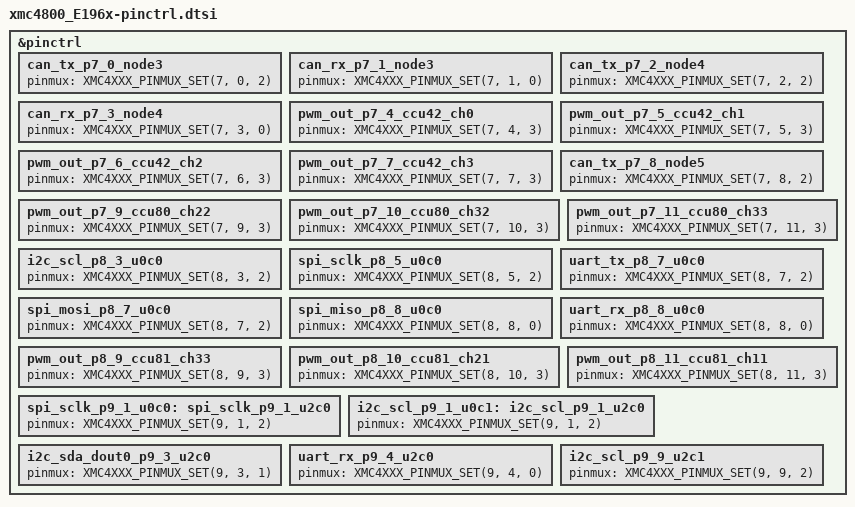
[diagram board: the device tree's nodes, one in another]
/*
 * SPDX-FileCopyrightText: Karl Palsson 2026 <karl.palsson@marel.com>
 * SPDX-License-Identifier: Apache-2.0
 */

#include <infineon/cat3/xmc/xmc4xxx.dtsi>
#include <zephyr/dt-bindings/pinctrl/xmc4xxx-pinctrl.h>
#include <infineon/cat3/xmc/xmc4700_F144x2048-pinctrl.dtsi>

&pinctrl {
	/omit-if-no-ref/ can_tx_p7_0_node3: can_tx_p7_0_node3 {
		pinmux = <XMC4XXX_PINMUX_SET(7, 0, 2)>;
	};

	/omit-if-no-ref/ can_rx_p7_1_node3: can_rx_p7_1_node3 {
		pinmux = <XMC4XXX_PINMUX_SET(7, 1, 0)>; /* CAN input src = RXDC */
	};

	/omit-if-no-ref/ can_tx_p7_2_node4: can_tx_p7_2_node4 {
		pinmux = <XMC4XXX_PINMUX_SET(7, 2, 2)>;
	};

	/omit-if-no-ref/ can_rx_p7_3_node4: can_rx_p7_3_node4 {
		pinmux = <XMC4XXX_PINMUX_SET(7, 3, 0)>; /* CAN input src = RXDC */
	};

	/omit-if-no-ref/ pwm_out_p7_4_ccu42_ch0: pwm_out_p7_4_ccu42_ch0 {
		pinmux = <XMC4XXX_PINMUX_SET(7, 4, 3)>;
	};

	/omit-if-no-ref/ pwm_out_p7_5_ccu42_ch1: pwm_out_p7_5_ccu42_ch1 {
		pinmux = <XMC4XXX_PINMUX_SET(7, 5, 3)>;
	};

	/omit-if-no-ref/ pwm_out_p7_6_ccu42_ch2: pwm_out_p7_6_ccu42_ch2 {
		pinmux = <XMC4XXX_PINMUX_SET(7, 6, 3)>;
	};

	/omit-if-no-ref/ pwm_out_p7_7_ccu42_ch3: pwm_out_p7_7_ccu42_ch3 {
		pinmux = <XMC4XXX_PINMUX_SET(7, 7, 3)>;
	};

	/omit-if-no-ref/ can_tx_p7_8_node5: can_tx_p7_8_node5 {
		pinmux = <XMC4XXX_PINMUX_SET(7, 8, 2)>;
	};

	/omit-if-no-ref/ pwm_out_p7_9_ccu80_ch22: pwm_out_p7_9_ccu80_ch22 {
		pinmux = <XMC4XXX_PINMUX_SET(7, 9, 3)>;
	};

	/omit-if-no-ref/ pwm_out_p7_10_ccu80_ch32: pwm_out_p7_10_ccu80_ch32 {
		pinmux = <XMC4XXX_PINMUX_SET(7, 10, 3)>;
	};

	/omit-if-no-ref/ pwm_out_p7_11_ccu80_ch33: pwm_out_p7_11_ccu80_ch33 {
		pinmux = <XMC4XXX_PINMUX_SET(7, 11, 3)>;
	};

	/omit-if-no-ref/ i2c_scl_p8_3_u0c0: i2c_scl_p8_3_u0c0 {
		pinmux = <XMC4XXX_PINMUX_SET(8, 3, 2)>; /* USIC scl-src = DX1C */
	};

	/omit-if-no-ref/ spi_sclk_p8_5_u0c0: spi_sclk_p8_5_u0c0 {
		pinmux = <XMC4XXX_PINMUX_SET(8, 5, 2)>;
	};

	/omit-if-no-ref/ uart_tx_p8_7_u0c0: uart_tx_p8_7_u0c0 {
		pinmux = <XMC4XXX_PINMUX_SET(8, 7, 2)>;
	};

	/omit-if-no-ref/ spi_mosi_p8_7_u0c0: spi_mosi_p8_7_u0c0 {
		pinmux = <XMC4XXX_PINMUX_SET(8, 7, 2)>;
	};

	/omit-if-no-ref/ spi_miso_p8_8_u0c0: spi_miso_p8_8_u0c0 {
		pinmux = <XMC4XXX_PINMUX_SET(8, 8, 0)>;	/* USIC input src = DX0E */
	};

	/omit-if-no-ref/ uart_rx_p8_8_u0c0: uart_rx_p8_8_u0c0 {
		pinmux = <XMC4XXX_PINMUX_SET(8, 8, 0)>;	/* USIC input src = DX0E */
	};

	/omit-if-no-ref/ pwm_out_p8_9_ccu81_ch33: pwm_out_p8_9_ccu81_ch33 {
		pinmux = <XMC4XXX_PINMUX_SET(8, 9, 3)>;
	};

	/omit-if-no-ref/ pwm_out_p8_10_ccu81_ch21: pwm_out_p8_10_ccu81_ch21 {
		pinmux = <XMC4XXX_PINMUX_SET(8, 10, 3)>;
	};

	/omit-if-no-ref/ pwm_out_p8_11_ccu81_ch11: pwm_out_p8_11_ccu81_ch11 {
		pinmux = <XMC4XXX_PINMUX_SET(8, 11, 3)>;
	};

	/omit-if-no-ref/ spi_sclk_p9_1_u0c0: spi_sclk_p9_1_u2c0 {
		pinmux = <XMC4XXX_PINMUX_SET(9, 1, 2)>;
	};

	/omit-if-no-ref/ i2c_scl_p9_1_u0c1: i2c_scl_p9_1_u2c0 {
		pinmux = <XMC4XXX_PINMUX_SET(9, 1, 2)>; /* USIC scl-src = DX1C */
	};

	/omit-if-no-ref/ i2c_sda_dout0_p9_3_u2c0: i2c_sda_dout0_p9_3_u2c0 {
		pinmux = <XMC4XXX_PINMUX_SET(9, 3, 1)>;
	};

	/omit-if-no-ref/ uart_rx_p9_4_u2c0: uart_rx_p9_4_u2c0 {
		pinmux = <XMC4XXX_PINMUX_SET(9, 4, 0)>;	/* USIC input src = DX0E */
	};

	/omit-if-no-ref/ i2c_scl_p9_9_u2c1: i2c_scl_p9_9_u2c1 {
		pinmux = <XMC4XXX_PINMUX_SET(9, 9, 2)>; /* USIC scl-src = DX1C */
	};
};
